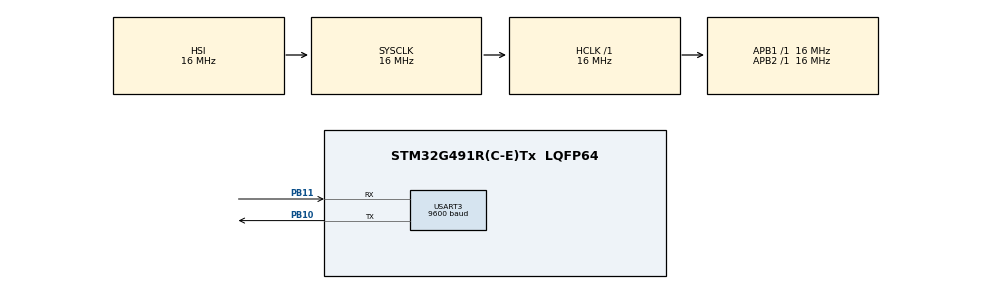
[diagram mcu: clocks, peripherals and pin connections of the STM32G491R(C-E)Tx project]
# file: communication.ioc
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Dma.Request0=USART3_RX
Dma.Request1=USART3_TX
Dma.USART3_RX.0.Direction=DMA_PERIPH_TO_MEMORY
Dma.USART3_RX.0.EventEnable=DISABLE
Dma.USART3_RX.0.Instance=DMA1_Channel1
Dma.USART3_RX.0.MemDataAlignment=DMA_MDATAALIGN_BYTE
Dma.USART3_RX.0.MemInc=DMA_MINC_ENABLE
Dma.USART3_RX.0.Mode=DMA_NORMAL
Dma.USART3_RX.0.PeriphDataAlignment=DMA_PDATAALIGN_BYTE
Dma.USART3_RX.0.PeriphInc=DMA_PINC_DISABLE
Dma.USART3_RX.0.Polarity=HAL_DMAMUX_REQ_GEN_RISING
Dma.USART3_RX.0.Priority=DMA_PRIORITY_LOW
Dma.USART3_RX.0.RequestNumber=1
Dma.USART3_RX.0.SignalID=NONE
Dma.USART3_RX.0.SyncEnable=DISABLE
Dma.USART3_RX.0.SyncPolarity=HAL_DMAMUX_SYNC_NO_EVENT
Dma.USART3_RX.0.SyncRequestNumber=1
Dma.USART3_RX.0.SyncSignalID=NONE
Dma.USART3_TX.1.Direction=DMA_MEMORY_TO_PERIPH
Dma.USART3_TX.1.EventEnable=DISABLE
Dma.USART3_TX.1.Instance=DMA1_Channel2
Dma.USART3_TX.1.MemDataAlignment=DMA_MDATAALIGN_BYTE
Dma.USART3_TX.1.MemInc=DMA_MINC_ENABLE
Dma.USART3_TX.1.Mode=DMA_NORMAL
Dma.USART3_TX.1.PeriphDataAlignment=DMA_PDATAALIGN_BYTE
Dma.USART3_TX.1.PeriphInc=DMA_PINC_DISABLE
Dma.USART3_TX.1.Polarity=HAL_DMAMUX_REQ_GEN_RISING
Dma.USART3_TX.1.Priority=DMA_PRIORITY_LOW
Dma.USART3_TX.1.RequestNumber=1
Dma.USART3_TX.1.SignalID=NONE
Dma.USART3_TX.1.SyncEnable=DISABLE
Dma.USART3_TX.1.SyncPolarity=HAL_DMAMUX_SYNC_NO_EVENT
Dma.USART3_TX.1.SyncRequestNumber=1
Dma.USART3_TX.1.SyncSignalID=NONE
Mcu.Family=STM32G4
Mcu.Name=STM32G491R(C-E)Tx
Mcu.Package=LQFP64
NVIC.DMA1_Channel1_IRQn=true\:0\:0\:false\:false\:true\:false\:true\:true
NVIC.DMA1_Channel2_IRQn=true\:0\:0\:false\:false\:true\:false\:true\:true
NVIC.PriorityGroup=NVIC_PRIORITYGROUP_4
NVIC.TIM6_DAC_IRQn=true\:0\:0\:false\:false\:true\:true\:true\:true
NVIC.USART3_IRQn=true\:0\:0\:false\:false\:true\:true\:true\:true
PB10.Mode=Asynchronous
PB10.Signal=USART3_TX
PB11.Mode=Asynchronous
PB11.Signal=USART3_RX
ProjectManager.HeapSize=0x200
ProjectManager.StackSize=0x400
ProjectManager.TargetToolchain=STM32CubeIDE
RCC.AHBFreq_Value=16000000
RCC.APB1Freq_Value=16000000
RCC.APB1TimFreq_Value=16000000
RCC.APB2Freq_Value=16000000
RCC.APB2TimFreq_Value=16000000
RCC.CortexFreq_Value=16000000
RCC.EXTERNAL_CLOCK_VALUE=12288000
RCC.HCLKFreq_Value=16000000
RCC.HSE_VALUE=8000000
RCC.HSI48_VALUE=48000000
RCC.HSI_VALUE=16000000
RCC.LSE_VALUE=32768
RCC.SYSCLKFreq_VALUE=16000000
RCC.USBFreq_Value=48000000
RCC.VCOOutputFreq_Value=128000000
TIM6.PeriodNoDither=10000-1
TIM6.Prescaler=1600-1
USART3.BaudRate=9600
USART3.VirtualMode-Asynchronous=VM_ASYNC
VP_TIM6_VS_ClockSourceINT.Mode=Enable_Timer
board=custom

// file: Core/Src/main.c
/* USER CODE BEGIN Header */
/**
  ******************************************************************************
  * @file           : main.c
  * @brief          : Main program body
  ******************************************************************************
  * @attention
  *
  * Copyright (c) 2024 STMicroelectronics.
  * All rights reserved.
  *
  * This software is licensed under terms that can be found in the LICENSE file
  * in the root directory of this software component.
  * If no LICENSE file comes with this software, it is provided AS-IS.
  *
  ******************************************************************************
  */
/* USER CODE END Header */
#include "main.h"

/* USER CODE BEGIN Includes */
#include "mainpp.h"
#include "string.h"
/* USER CODE END Includes */

TIM_HandleTypeDef htim6;

UART_HandleTypeDef huart3;
DMA_HandleTypeDef hdma_usart3_rx;
DMA_HandleTypeDef hdma_usart3_tx;

void SystemClock_Config(void);
static void MX_GPIO_Init(void);
static void MX_DMA_Init(void);
static void MX_USART3_UART_Init(void);
static void MX_TIM6_Init(void);

int main(void)
{

  /* MCU Configuration--------------------------------------------------------*/

  /* Reset of all peripherals, Initializes the Flash interface and the Systick. */
  HAL_Init();

  /* Configure the system clock */
  SystemClock_Config();

  /* Initialize all configured peripherals */
  MX_GPIO_Init();
  MX_DMA_Init();
  MX_USART3_UART_Init();
  MX_TIM6_Init();
  /* USER CODE BEGIN 2 */
  main_function();
  /* USER CODE END 2 */

  /* Infinite loop */
  while (1)
  {

  }
}

void SystemClock_Config(void)
{
  RCC_OscInitTypeDef RCC_OscInitStruct = {0};
  RCC_ClkInitTypeDef RCC_ClkInitStruct = {0};

  /** Configure the main internal regulator output voltage
  */
  HAL_PWREx_ControlVoltageScaling(PWR_REGULATOR_VOLTAGE_SCALE1);

  /** Initializes the RCC Oscillators according to the specified parameters
  * in the RCC_OscInitTypeDef structure.
  */
  RCC_OscInitStruct.OscillatorType = RCC_OSCILLATORTYPE_HSI;
  RCC_OscInitStruct.HSIState = RCC_HSI_ON;
  RCC_OscInitStruct.HSICalibrationValue = RCC_HSICALIBRATION_DEFAULT;
  RCC_OscInitStruct.PLL.PLLState = RCC_PLL_NONE;
  if (HAL_RCC_OscConfig(&RCC_OscInitStruct) != HAL_OK)
  {
    Error_Handler();
  }

  /** Initializes the CPU, AHB and APB buses clocks
  */
  RCC_ClkInitStruct.ClockType = RCC_CLOCKTYPE_HCLK|RCC_CLOCKTYPE_SYSCLK
                              |RCC_CLOCKTYPE_PCLK1|RCC_CLOCKTYPE_PCLK2;
  RCC_ClkInitStruct.SYSCLKSource = RCC_SYSCLKSOURCE_HSI;
  RCC_ClkInitStruct.AHBCLKDivider = RCC_SYSCLK_DIV1;
  RCC_ClkInitStruct.APB1CLKDivider = RCC_HCLK_DIV1;
  RCC_ClkInitStruct.APB2CLKDivider = RCC_HCLK_DIV1;

  if (HAL_RCC_ClockConfig(&RCC_ClkInitStruct, FLASH_LATENCY_0) != HAL_OK)
  {
    Error_Handler();
  }
}

static void MX_TIM6_Init(void)
{

  TIM_MasterConfigTypeDef sMasterConfig = {0};

  htim6.Instance = TIM6;
  htim6.Init.Prescaler = 1600-1;
  htim6.Init.CounterMode = TIM_COUNTERMODE_UP;
  htim6.Init.Period = 9999;
  htim6.Init.AutoReloadPreload = TIM_AUTORELOAD_PRELOAD_DISABLE;
  if (HAL_TIM_Base_Init(&htim6) != HAL_OK)
  {
    Error_Handler();
  }
  sMasterConfig.MasterOutputTrigger = TIM_TRGO_RESET;
  sMasterConfig.MasterSlaveMode = TIM_MASTERSLAVEMODE_DISABLE;
  if (HAL_TIMEx_MasterConfigSynchronization(&htim6, &sMasterConfig) != HAL_OK)
  {
    Error_Handler();
  }

}

static void MX_USART3_UART_Init(void)
{

  huart3.Instance = USART3;
  huart3.Init.BaudRate = 9600;
  huart3.Init.WordLength = UART_WORDLENGTH_8B;
  huart3.Init.StopBits = UART_STOPBITS_1;
  huart3.Init.Parity = UART_PARITY_NONE;
  huart3.Init.Mode = UART_MODE_TX_RX;
  huart3.Init.HwFlowCtl = UART_HWCONTROL_NONE;
  huart3.Init.OverSampling = UART_OVERSAMPLING_16;
  huart3.Init.OneBitSampling = UART_ONE_BIT_SAMPLE_DISABLE;
  huart3.Init.ClockPrescaler = UART_PRESCALER_DIV1;
  huart3.AdvancedInit.AdvFeatureInit = UART_ADVFEATURE_NO_INIT;
  if (HAL_UART_Init(&huart3) != HAL_OK)
  {
    Error_Handler();
  }
  if (HAL_UARTEx_SetTxFifoThreshold(&huart3, UART_TXFIFO_THRESHOLD_1_8) != HAL_OK)
  {
    Error_Handler();
  }
  if (HAL_UARTEx_SetRxFifoThreshold(&huart3, UART_RXFIFO_THRESHOLD_1_8) != HAL_OK)
  {
    Error_Handler();
  }
  if (HAL_UARTEx_DisableFifoMode(&huart3) != HAL_OK)
  {
    Error_Handler();
  }

}

static void MX_DMA_Init(void)
{

  /* DMA controller clock enable */
  __HAL_RCC_DMAMUX1_CLK_ENABLE();
  __HAL_RCC_DMA1_CLK_ENABLE();

  /* DMA interrupt init */
  /* DMA1_Channel1_IRQn interrupt configuration */
  HAL_NVIC_SetPriority(DMA1_Channel1_IRQn, 0, 0);
  HAL_NVIC_EnableIRQ(DMA1_Channel1_IRQn);
  /* DMA1_Channel2_IRQn interrupt configuration */
  HAL_NVIC_SetPriority(DMA1_Channel2_IRQn, 0, 0);
  HAL_NVIC_EnableIRQ(DMA1_Channel2_IRQn);

}

static void MX_GPIO_Init(void)
{

  /* GPIO Ports Clock Enable */
  __HAL_RCC_GPIOB_CLK_ENABLE();

}

void Error_Handler(void)
{
  __disable_irq();
  while (1)
  {
  }
}
